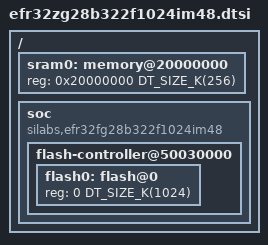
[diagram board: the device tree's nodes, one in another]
/*
 * Copyright (c) 2019 Steven Lemaire
 *
 * SPDX-License-Identifier: Apache-2.0
 */

#include <mem.h>
#include <silabs/efr32zg28.dtsi>

/ {
	sram0: memory@20000000 {
		reg = <0x20000000 DT_SIZE_K(256)>;
	};

	soc {
		compatible = "silabs,efr32fg28b322f1024im48",
					 "silabs,efr32fg28", "silabs,efr32",
					 "simple-bus";

		flash-controller@50030000 {
			flash0: flash@0 {
				reg = <0 DT_SIZE_K(1024)>;
			};
		};
	};
};
